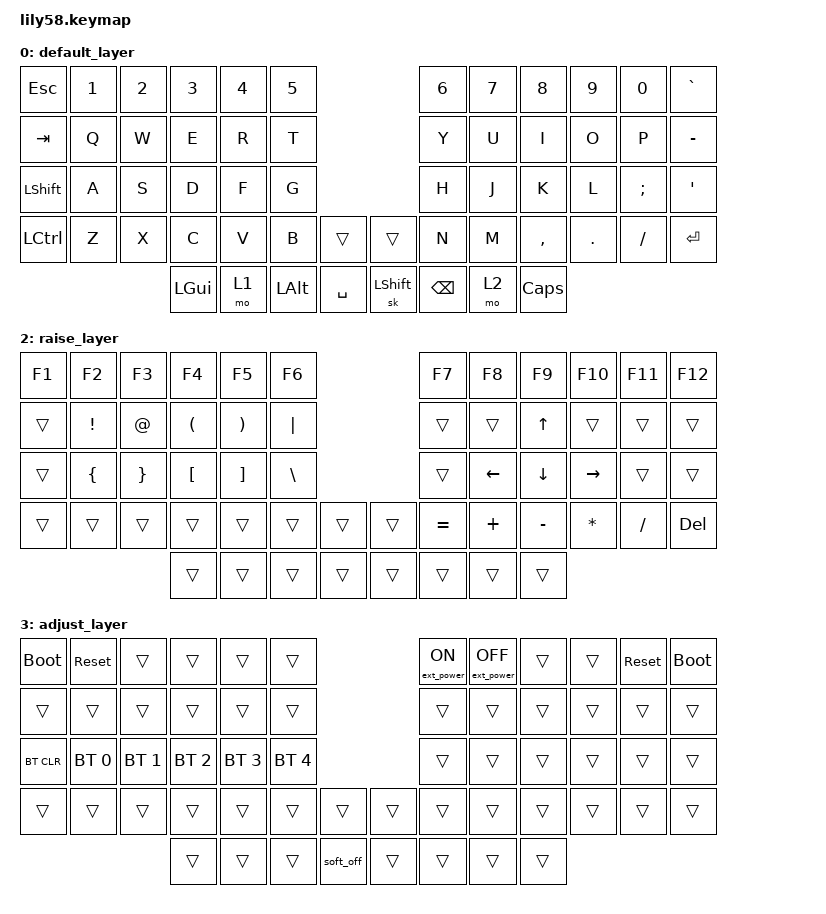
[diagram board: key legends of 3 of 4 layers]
/*
 * Copyright (c) 2020 The ZMK Contributors
 *
 * SPDX-License-Identifier: MIT
 */

#include <behaviors.dtsi>
#include <dt-bindings/zmk/keys.h>
#include <dt-bindings/zmk/bt.h>
#include <dt-bindings/zmk/ext_power.h>

&soft_off {
    hold-time-ms = <3000>; // Only turn off it the key is held for 3 seconds or longer.
};

/ {

    behaviors {
        sk: sticky_key {
            compatible = "zmk,behavior-sticky-key";
            #binding-cells = <1>;
            release-after-ms = <2000>;
            //quick-release;
        };
    };
    
    keymap {
        compatible = "zmk,keymap";

        default_layer {
// ------------------------------------------------------------------------------------------------------------
// |  ESC  |  1  |  2  |  3   |  4   |  5   |                   |  6   |  7    |  8    |  9   |   0   |   `   |
// |  TAB  |  Q  |  W  |  E   |  R   |  T   |                   |  Y   |  U    |  I    |  O   |   P   |   -   |
// | SHIFT |  A  |  S  |  D   |  F   |  G   |                   |  H   |  J    |  K    |  L   |   ;   |   '   |
// | CTRL  |  Z  |  X  |  C   |  V   |  B   |   "["  |  |  "]"  |  N   |  M    |  ,    |  .   |   /   | ENTER |
//                     | GUI | LOWER | ALT |  SPACE |  | ENTER | BSPC | RAISE | CAPS   |
            bindings = <
&kp ESC   &kp N1 &kp N2 &kp N3   &kp N4   &kp N5                            &kp N6  &kp N7   &kp N8    &kp N9  &kp N0   &kp GRAVE
&kp TAB   &kp Q  &kp W  &kp E    &kp R    &kp T                             &kp Y   &kp U    &kp I     &kp O   &kp P    &kp MINUS
&kp LSHFT &kp A  &kp S &kp D    &kp F    &kp G                             &kp H   &kp J    &kp K     &kp L   &kp SEMI &kp SQT
&kp LCTRL &kp Z  &kp X  &kp C    &kp V    &kp B      &trans     &trans      &kp N   &kp M    &kp COMMA &kp DOT &kp FSLH &kp RET
                        &kp LGUI &mo 1    &kp LALT   &kp SPACE  &sk LSHFT   &kp BSPC &mo 2   &kp CAPS
            >;

            sensor-bindings = <&inc_dec_kp C_VOL_UP C_VOL_DN>;
        };

        lower_layer {

            bindings = <
&trans     &trans    &trans   &trans     &trans      &trans                               &trans      &trans      &trans    &trans    &trans      &trans
&trans     &kp EXCL  &kp AT   &kp HASH   &kp DOLLAR  &kp PRCNT                            &CARET      &kp AMPS    &kp ASTRK &kp LPAR  &kp RPAR    &trans
&kp GRAVE  &kp N1    &kp N2   &kp N3     &kp N4      &kp N5                               &kp N6      &kp N7      &kp N8    &kp N9    &kp N0      &kp TILDE
&trans     &ext_power EP_ON &ext_power EP_OFF &ext_power EP_TOG &trans       &trans       &trans      &kp MINUS   &kp PLUS  &kp LBRC  &kp RBRC    &kp PIPE
                                              &trans            &trans       &trans       &trans  &trans      &trans    &trans    &trans
            >;

            sensor-bindings = <&inc_dec_kp C_VOL_UP C_VOL_DN>;
        };

        raise_layer {

            bindings = <
&kp F1    &kp F2    &kp F3   &kp F4     &kp F5      &kp F6                          &kp F7      &kp F8      &kp F9    &kp F10   &kp F11     &kp F12 
&trans    &kp EXCL  &kp AT   &kp LPAR   &kp RPAR    &kp PIPE                        &trans      &trans      &kp UP    &trans    &trans      &trans
&trans    &kp LBRC  &kp RBRC &kp LBKT   &kp RBKT    &kp BSLH                        &trans      &kp LEFT    &kp DOWN  &kp RIGHT &trans      &trans
&trans    &trans    &trans   &trans     &trans      &trans       &trans   &trans    &kp EQUAL   &kp PLUS    &kp MINUS &kp ASTRK &kp FSLH    &kp DEL
                                        &trans  &trans  &trans  &trans    &trans   &trans    &trans    &trans
            >;                                                                         

            sensor-bindings = <&inc_dec_kp C_VOL_UP C_VOL_DN>;
        };

         adjust_layer {

            bindings = <
&bootloader &sys_reset &trans &trans &trans &trans                                      &ext_power EP_ON &ext_power EP_OFF &trans &trans &sys_reset &bootloader
&trans      &trans      &trans      &trans        &trans                  &trans      &trans           &trans            &trans &trans &trans &trans
&bt BT_CLR  &bt BT_SEL 0 &bt BT_SEL 1 &bt BT_SEL 2 &bt BT_SEL 3 &bt BT_SEL 4            &trans &trans &trans &trans &trans &trans
&trans      &trans     &trans &trans &trans &trans &trans &trans                        &trans &trans &trans &trans &trans &trans
                                                    &trans &trans &trans &soft_off   &trans &trans &trans &trans
            >;

            sensor-bindings = <&inc_dec_kp C_VOL_UP C_VOL_DN>;
        };
    };

    conditional_layers {
        compatible = "zmk,conditional-layers";

        adjust {
            if-layers = <1 2>;
            then-layer = <3>;
        };
    };
};
